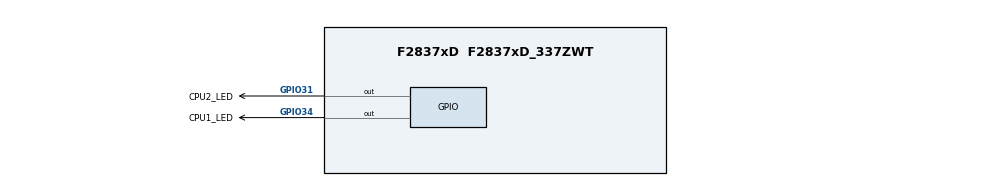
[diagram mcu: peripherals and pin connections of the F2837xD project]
/**
 * @cliArgs --device "F2837xD" --package "F2837xD_337ZWT" --part "F2837xD_337ZWT" --context "CPU1" --product "C2000WARE@5.01.00.00"
 * @versions {"tool":"1.19.0+3426"}
 */
scripting.excludeFromBuild("c2000ware_libraries.cmd.genlibs");

/**
 * Import the modules used in this configuration.
 */
const gpio   = scripting.addModule("/driverlib/gpio.js", {}, false);
const gpio1  = gpio.addInstance();
const gpio2  = gpio.addInstance();
const ipc    = scripting.addModule("/driverlib/ipc.js");
const memcfg = scripting.addModule("/driverlib/memcfg.js");

/**
 * Write custom configuration values to the imported modules.
 */
gpio1.$name           = "CPU1_LED";
gpio1.direction       = "GPIO_DIR_MODE_OUT";
gpio1.gpioPin.$assign = "GPIO34";

gpio2.$name           = "CPU2_LED";
gpio2.direction       = "GPIO_DIR_MODE_OUT";
gpio2.controllerCore  = "GPIO_CORE_CPU2";
gpio2.gpioPin.$assign = "GPIO31";

memcfg.config_MEMCFG_SECT_GS0  = "MEMCFG_GSRAMCONTROLLER_CPU2";
memcfg.config_MEMCFG_SECT_GS14 = "MEMCFG_GSRAMCONTROLLER_CPU2";
